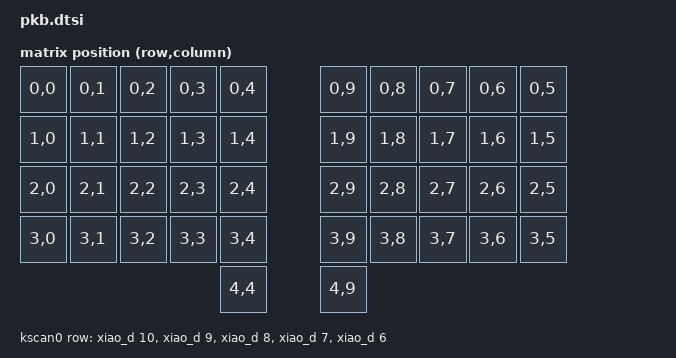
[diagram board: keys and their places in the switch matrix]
// This file was generated from a template. Edit it to match your keyboard.
// See https://zmk.dev/docs/development/hardware-integration/new-shield for more
// instructions.

#include <dt-bindings/zmk/matrix_transform.h>
#include <dt-bindings/led/led.h>

#include "pkb-layouts.dtsi"

/ {
    chosen {
        zmk,kscan = &kscan0;
        zmk,physical-layout = &default_layout;
        zmk,underglow = &led_strip; 
    };
    default_layout: physical_layout0 {
        compatible = "zmk,physical-layout";
        display-name = "PKB 40% Standard";
        transform = <&default_transform>;
    };

    kscan0: kscan0 {
        // If the hardware does not use a switch matrix, change this to the
        // appropriate driver and update the properties below to match.
        // See https://zmk.dev/docs/config/kscan for supported key scan drivers.
        compatible = "zmk,kscan-gpio-matrix";
        // Set this to "col2row" or "row2col" to match the hardware. If using
        // "row2col", change the col-gpios in the _left.overlay and _right.overlay
        // files to (GPIO_ACTIVE_HIGH | GPIO_PULL_DOWN) and the row-gpios here to
        // GPIO_ACTIVE_HIGH.
        diode-direction = "col2row";
        wakeup-source;

        // Replace these comments with the GPIO pins in the matrix.
        // See https://zmk.dev/docs/development/hardware-integration/new-shield#shield-overlays
        row-gpios
            = <&xiao_d 10 (GPIO_ACTIVE_HIGH | GPIO_PULL_DOWN)>
            , <&xiao_d 9 (GPIO_ACTIVE_HIGH | GPIO_PULL_DOWN)>
            , <&xiao_d 8 (GPIO_ACTIVE_HIGH | GPIO_PULL_DOWN)>
            , <&xiao_d 7 (GPIO_ACTIVE_HIGH | GPIO_PULL_DOWN)>
            , <&xiao_d 6 (GPIO_ACTIVE_HIGH | GPIO_PULL_DOWN)>
            ;
    };
};


/ {
    default_transform: keymap_transform_0 {
        compatible = "zmk,matrix-transform";
        columns = <10>; // 5 columns on the left + 5 columns on the right
        rows = <5>;     // 4 main rows + 1 extra row for the thumb key

        map = <
        // Left Half (Cols 0-4)                      // Right Half (Cols 5-9)
        RC(0,0) RC(0,1) RC(0,2) RC(0,3) RC(0,4)      RC(0,9) RC(0,8) RC(0,7) RC(0,6) RC(0,5)
        RC(1,0) RC(1,1) RC(1,2) RC(1,3) RC(1,4)      RC(1,9) RC(1,8) RC(1,7) RC(1,6) RC(1,5)
        RC(2,0) RC(2,1) RC(2,2) RC(2,3) RC(2,4)      RC(2,9) RC(2,8) RC(2,7) RC(2,6) RC(2,5)
        RC(3,0) RC(3,1) RC(3,2) RC(3,3) RC(3,4)      RC(3,9) RC(3,8) RC(3,7) RC(3,6) RC(3,5)
                                        RC(4,4)      RC(4,9)
        >;
    };

};

/ {
    ext-power {
        compatible = "zmk,ext-power-generic";
        label = "EXT_POWER";
        control-gpios = <&gpio0 9 GPIO_ACTIVE_HIGH>; 
    };
};

&pinctrl {
    spi2_default: spi2_default {
        group1 {
            psels = <NRF_PSEL(SPIM_MOSI, 1, 11)>; 
        };
    };
    spi2_sleep: spi2_sleep {
        group1 {
            psels = <NRF_PSEL(SPIM_MOSI, 1, 11)>;
            low-power-enable;
        };
    };
};

&spi2 {
    compatible = "nordic,nrf-spim";
    status = "okay";
    pinctrl-0 = <&spi2_default>;
    pinctrl-1 = <&spi2_sleep>;
    pinctrl-names = "default", "sleep";

    led_strip: ws2812@0 {
        compatible = "worldsemi,ws2812-spi";
        label = "SK6812";
        reg = <0>;
        spi-max-frequency = <4000000>;
        chain-length = <21>; // 21 LEDs per board half!
        spi-one-frame = <0x70>;
        spi-zero-frame = <0x40>;
        color-mapping = <LED_COLOR_ID_GREEN LED_COLOR_ID_RED LED_COLOR_ID_BLUE>;
    };
};

